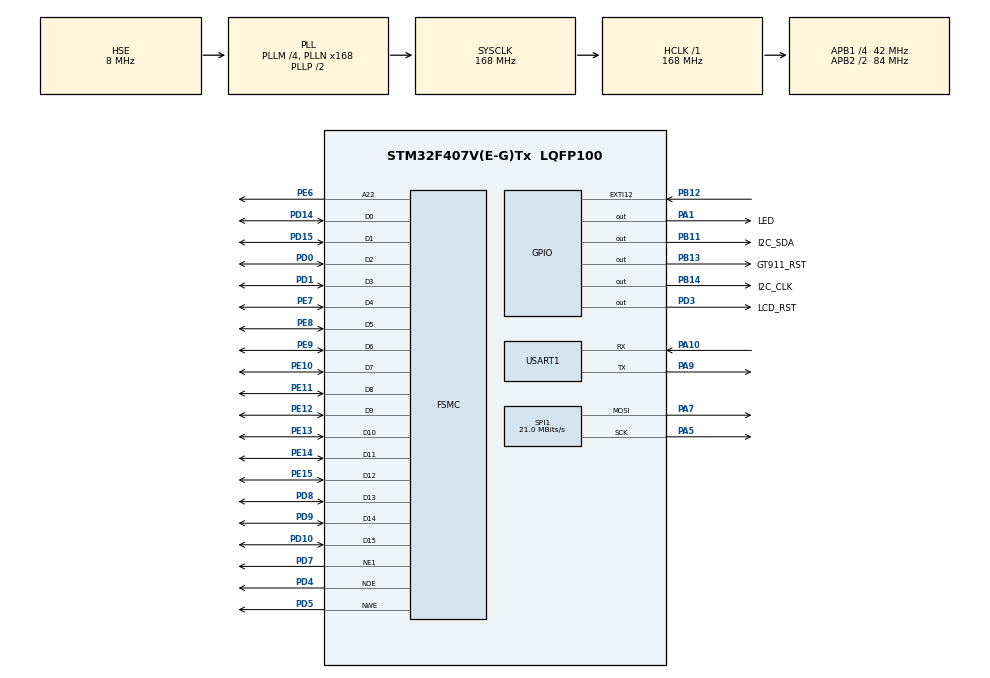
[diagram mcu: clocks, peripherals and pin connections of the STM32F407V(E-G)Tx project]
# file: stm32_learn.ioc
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Dma.MEMTOMEM.0.Direction=DMA_MEMORY_TO_MEMORY
Dma.MEMTOMEM.0.FIFOMode=DMA_FIFOMODE_ENABLE
Dma.MEMTOMEM.0.FIFOThreshold=DMA_FIFO_THRESHOLD_FULL
Dma.MEMTOMEM.0.Instance=DMA2_Stream0
Dma.MEMTOMEM.0.MemBurst=DMA_MBURST_SINGLE
Dma.MEMTOMEM.0.MemDataAlignment=DMA_MDATAALIGN_HALFWORD
Dma.MEMTOMEM.0.MemInc=DMA_MINC_DISABLE
Dma.MEMTOMEM.0.Mode=DMA_NORMAL
Dma.MEMTOMEM.0.PeriphBurst=DMA_PBURST_SINGLE
Dma.MEMTOMEM.0.PeriphDataAlignment=DMA_PDATAALIGN_HALFWORD
Dma.MEMTOMEM.0.PeriphInc=DMA_PINC_ENABLE
Dma.MEMTOMEM.0.Priority=DMA_PRIORITY_HIGH
Dma.Request0=MEMTOMEM
FSMC.AddressSetupTime1=1
FSMC.BusTurnAroundDuration1=0
FSMC.DataSetupTime1=1
FSMC.ExtendedMode1=FSMC_EXTENDED_MODE_DISABLE
Mcu.Family=STM32F4
Mcu.Name=STM32F407V(E-G)Tx
Mcu.Package=LQFP100
NVIC.PriorityGroup=NVIC_PRIORITYGROUP_4
PA1.GPIO_Label=LED
PA1.Signal=GPIO_Output
PA10.Mode=Asynchronous
PA10.Signal=USART1_RX
PA13.Mode=Serial_Wire
PA13.Signal=SYS_JTMS-SWDIO
PA14.Mode=Serial_Wire
PA14.Signal=SYS_JTCK-SWCLK
PA5.Mode=TX_Only_Simplex_Unidirect_Master
PA5.Signal=SPI1_SCK
PA7.Mode=TX_Only_Simplex_Unidirect_Master
PA7.Signal=SPI1_MOSI
PA9.Mode=Asynchronous
PA9.Signal=USART1_TX
PB11.GPIO_Label=I2C_SDA
PB11.GPIO_ModeDefaultOutputPP=GPIO_MODE_OUTPUT_PP
PB11.GPIO_PuPd=GPIO_PULLUP
PB11.GPIO_Speed=GPIO_SPEED_FREQ_HIGH
PB11.Signal=GPIO_Output
PB12.Signal=GPXTI12
PB13.GPIO_Label=GT911_RST
PB13.GPIO_PuPd=GPIO_PULLUP
PB13.PinState=GPIO_PIN_RESET
PB13.Signal=GPIO_Output
PB14.GPIO_Label=I2C_CLK
PB14.GPIO_ModeDefaultOutputPP=GPIO_MODE_OUTPUT_PP
PB14.GPIO_PuPd=GPIO_PULLUP
PB14.GPIO_Speed=GPIO_SPEED_FREQ_HIGH
PB14.Signal=GPIO_Output
PC14-OSC32_IN.Mode=LSE-External-Oscillator
PC14-OSC32_IN.Signal=RCC_OSC32_IN
PC15-OSC32_OUT.Mode=LSE-External-Oscillator
PC15-OSC32_OUT.Signal=RCC_OSC32_OUT
PD0.Mode=16b-d1
PD0.Signal=FSMC_D2
PD1.Mode=16b-d1
PD1.Signal=FSMC_D3
PD10.Mode=16b-d1
PD10.Signal=FSMC_D15
PD14.Mode=16b-d1
PD14.Signal=FSMC_D0
PD15.Mode=16b-d1
PD15.Signal=FSMC_D1
PD3.GPIO_Label=LCD_RST
PD3.Signal=GPIO_Output
PD4.Mode=Lcd1
PD4.Signal=FSMC_NOE
PD5.Mode=Lcd1
PD5.Signal=FSMC_NWE
PD7.Mode=NorPsramChipSelect1_1
PD7.Signal=FSMC_NE1
PD8.Mode=16b-d1
PD8.Signal=FSMC_D13
PD9.Mode=16b-d1
PD9.Signal=FSMC_D14
PE10.Mode=16b-d1
PE10.Signal=FSMC_D7
PE11.Mode=16b-d1
PE11.Signal=FSMC_D8
PE12.Mode=16b-d1
PE12.Signal=FSMC_D9
PE13.Mode=16b-d1
PE13.Signal=FSMC_D10
PE14.Mode=16b-d1
PE14.Signal=FSMC_D11
PE15.Mode=16b-d1
PE15.Signal=FSMC_D12
PE6.Mode=A22_1
PE6.Signal=FSMC_A22
PE7.Mode=16b-d1
PE7.Signal=FSMC_D4
PE8.Mode=16b-d1
PE8.Signal=FSMC_D5
PE9.Mode=16b-d1
PE9.Signal=FSMC_D6
PH0-OSC_IN.Mode=HSE-External-Oscillator
PH0-OSC_IN.Signal=RCC_OSC_IN
PH1-OSC_OUT.Mode=HSE-External-Oscillator
PH1-OSC_OUT.Signal=RCC_OSC_OUT
ProjectManager.HeapSize=0x200
ProjectManager.StackSize=0x400
ProjectManager.TargetToolchain=CMake
RCC.48MHZClocksFreq_Value=84000000
RCC.AHBFreq_Value=168000000
RCC.APB1CLKDivider=RCC_HCLK_DIV4
RCC.APB1Freq_Value=42000000
RCC.APB1TimFreq_Value=84000000
RCC.APB2CLKDivider=RCC_HCLK_DIV2
RCC.APB2Freq_Value=84000000
RCC.APB2TimFreq_Value=168000000
RCC.CortexFreq_Value=168000000
RCC.HCLKFreq_Value=168000000
RCC.HSE_VALUE=8000000
RCC.HSI_VALUE=16000000
RCC.PLLM=4
RCC.PLLMUL=RCC_PLL_MUL9
RCC.PLLN=168
RCC.PLLSourceVirtual=RCC_PLLSOURCE_HSE
RCC.SYSCLKFreq_VALUE=168000000
RCC.SYSCLKSource=RCC_SYSCLKSOURCE_PLLCLK
RCC.USBFreq_Value=72000000
RCC.VCOOutputFreq_Value=336000000
SPI1.BaudRatePrescaler=SPI_BAUDRATEPRESCALER_4
SPI1.CLKPhase=SPI_PHASE_1EDGE
SPI1.CLKPolarity=SPI_POLARITY_LOW
SPI1.CalculateBaudRate=21.0 MBits/s
SPI1.Direction=SPI_DIRECTION_2LINES
SPI1.Mode=SPI_MODE_MASTER
SPI1.VirtualType=VM_MASTER
USART1.VirtualMode=VM_ASYNC
board=custom

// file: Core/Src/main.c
/* USER CODE BEGIN Header */
/**
  ******************************************************************************
  * @file           : main.c
  * @brief          : Main program body
  ******************************************************************************
  * @attention
  *
  * Copyright (c) 2026 STMicroelectronics.
  * All rights reserved.
  *
  * This software is licensed under terms that can be found in the LICENSE file
  * in the root directory of this software component.
  * If no LICENSE file comes with this software, it is provided AS-IS.
  *
  ******************************************************************************
  */
/* USER CODE END Header */
#include "main.h"

SPI_HandleTypeDef hspi1;

UART_HandleTypeDef huart1;

DMA_HandleTypeDef hdma_memtomem_dma2_stream0;
SRAM_HandleTypeDef hsram1;

void SystemClock_Config(void);
static void MX_GPIO_Init(void);
static void MX_DMA_Init(void);
static void MX_FSMC_Init(void);
static void MX_SPI1_Init(void);
static void MX_USART1_UART_Init(void);

/* USER CODE BEGIN 0 */
int mymain(void);
/* USER CODE END 0 */

int main(void)
{

  /* MCU Configuration--------------------------------------------------------*/

  /* Reset of all peripherals, Initializes the Flash interface and the Systick. */
  HAL_Init();

  /* Configure the system clock */
  SystemClock_Config();

  /* Initialize all configured peripherals */
  MX_GPIO_Init();
  MX_DMA_Init();
  MX_FSMC_Init();
  MX_SPI1_Init();
  MX_USART1_UART_Init();
  /* USER CODE BEGIN 2 */
    if (mymain() != 0)
    {
      Error_Handler();
    }

  /* USER CODE END 2 */

  /* Infinite loop */
  while (1)
  {

  }
}

void SystemClock_Config(void)
{
  RCC_OscInitTypeDef RCC_OscInitStruct = {0};
  RCC_ClkInitTypeDef RCC_ClkInitStruct = {0};

  /** Configure the main internal regulator output voltage
  */
  __HAL_RCC_PWR_CLK_ENABLE();
  __HAL_PWR_VOLTAGESCALING_CONFIG(PWR_REGULATOR_VOLTAGE_SCALE1);

  /** Initializes the RCC Oscillators according to the specified parameters
  * in the RCC_OscInitTypeDef structure.
  */
  RCC_OscInitStruct.OscillatorType = RCC_OSCILLATORTYPE_HSE;
  RCC_OscInitStruct.HSEState = RCC_HSE_ON;
  RCC_OscInitStruct.PLL.PLLState = RCC_PLL_ON;
  RCC_OscInitStruct.PLL.PLLSource = RCC_PLLSOURCE_HSE;
  RCC_OscInitStruct.PLL.PLLM = 4;
  RCC_OscInitStruct.PLL.PLLN = 168;
  RCC_OscInitStruct.PLL.PLLP = RCC_PLLP_DIV2;
  RCC_OscInitStruct.PLL.PLLQ = 4;
  if (HAL_RCC_OscConfig(&RCC_OscInitStruct) != HAL_OK)
  {
    Error_Handler();
  }

  /** Initializes the CPU, AHB and APB buses clocks
  */
  RCC_ClkInitStruct.ClockType = RCC_CLOCKTYPE_HCLK|RCC_CLOCKTYPE_SYSCLK
                              |RCC_CLOCKTYPE_PCLK1|RCC_CLOCKTYPE_PCLK2;
  RCC_ClkInitStruct.SYSCLKSource = RCC_SYSCLKSOURCE_PLLCLK;
  RCC_ClkInitStruct.AHBCLKDivider = RCC_SYSCLK_DIV1;
  RCC_ClkInitStruct.APB1CLKDivider = RCC_HCLK_DIV4;
  RCC_ClkInitStruct.APB2CLKDivider = RCC_HCLK_DIV2;

  if (HAL_RCC_ClockConfig(&RCC_ClkInitStruct, FLASH_LATENCY_5) != HAL_OK)
  {
    Error_Handler();
  }
}

static void MX_SPI1_Init(void)
{

  /* SPI1 parameter configuration*/
  hspi1.Instance = SPI1;
  hspi1.Init.Mode = SPI_MODE_MASTER;
  hspi1.Init.Direction = SPI_DIRECTION_2LINES;
  hspi1.Init.DataSize = SPI_DATASIZE_8BIT;
  hspi1.Init.CLKPolarity = SPI_POLARITY_LOW;
  hspi1.Init.CLKPhase = SPI_PHASE_1EDGE;
  hspi1.Init.NSS = SPI_NSS_SOFT;
  hspi1.Init.BaudRatePrescaler = SPI_BAUDRATEPRESCALER_4;
  hspi1.Init.FirstBit = SPI_FIRSTBIT_MSB;
  hspi1.Init.TIMode = SPI_TIMODE_DISABLE;
  hspi1.Init.CRCCalculation = SPI_CRCCALCULATION_DISABLE;
  hspi1.Init.CRCPolynomial = 10;
  if (HAL_SPI_Init(&hspi1) != HAL_OK)
  {
    Error_Handler();
  }

}

static void MX_USART1_UART_Init(void)
{

  huart1.Instance = USART1;
  huart1.Init.BaudRate = 115200;
  huart1.Init.WordLength = UART_WORDLENGTH_8B;
  huart1.Init.StopBits = UART_STOPBITS_1;
  huart1.Init.Parity = UART_PARITY_NONE;
  huart1.Init.Mode = UART_MODE_TX_RX;
  huart1.Init.HwFlowCtl = UART_HWCONTROL_NONE;
  huart1.Init.OverSampling = UART_OVERSAMPLING_16;
  if (HAL_UART_Init(&huart1) != HAL_OK)
  {
    Error_Handler();
  }

}

static void MX_DMA_Init(void)
{

  /* DMA controller clock enable */
  __HAL_RCC_DMA2_CLK_ENABLE();

  /* Configure DMA request hdma_memtomem_dma2_stream0 on DMA2_Stream0 */
  hdma_memtomem_dma2_stream0.Instance = DMA2_Stream0;
  hdma_memtomem_dma2_stream0.Init.Channel = DMA_CHANNEL_0;
  hdma_memtomem_dma2_stream0.Init.Direction = DMA_MEMORY_TO_MEMORY;
  hdma_memtomem_dma2_stream0.Init.PeriphInc = DMA_PINC_ENABLE;
  hdma_memtomem_dma2_stream0.Init.MemInc = DMA_MINC_DISABLE;
  hdma_memtomem_dma2_stream0.Init.PeriphDataAlignment = DMA_PDATAALIGN_HALFWORD;
  hdma_memtomem_dma2_stream0.Init.MemDataAlignment = DMA_MDATAALIGN_HALFWORD;
  hdma_memtomem_dma2_stream0.Init.Mode = DMA_NORMAL;
  hdma_memtomem_dma2_stream0.Init.Priority = DMA_PRIORITY_HIGH;
  hdma_memtomem_dma2_stream0.Init.FIFOMode = DMA_FIFOMODE_ENABLE;
  hdma_memtomem_dma2_stream0.Init.FIFOThreshold = DMA_FIFO_THRESHOLD_FULL;
  hdma_memtomem_dma2_stream0.Init.MemBurst = DMA_MBURST_SINGLE;
  hdma_memtomem_dma2_stream0.Init.PeriphBurst = DMA_PBURST_SINGLE;
  if (HAL_DMA_Init(&hdma_memtomem_dma2_stream0) != HAL_OK)
  {
    Error_Handler( );
  }

}

static void MX_GPIO_Init(void)
{
  GPIO_InitTypeDef GPIO_InitStruct = {0};

  /* GPIO Ports Clock Enable */
  __HAL_RCC_GPIOE_CLK_ENABLE();
  __HAL_RCC_GPIOC_CLK_ENABLE();
  __HAL_RCC_GPIOH_CLK_ENABLE();
  __HAL_RCC_GPIOA_CLK_ENABLE();
  __HAL_RCC_GPIOB_CLK_ENABLE();
  __HAL_RCC_GPIOD_CLK_ENABLE();

  /*Configure GPIO pin Output Level */
  HAL_GPIO_WritePin(LED_GPIO_Port, LED_Pin, GPIO_PIN_RESET);

  /*Configure GPIO pin Output Level */
  HAL_GPIO_WritePin(GPIOB, I2C_SDA_Pin|GT911_RST_Pin|I2C_CLK_Pin, GPIO_PIN_RESET);

  /*Configure GPIO pin Output Level */
  HAL_GPIO_WritePin(LCD_RST_GPIO_Port, LCD_RST_Pin, GPIO_PIN_RESET);

  /*Configure GPIO pin : LED_Pin */
  GPIO_InitStruct.Pin = LED_Pin;
  GPIO_InitStruct.Mode = GPIO_MODE_OUTPUT_PP;
  GPIO_InitStruct.Pull = GPIO_NOPULL;
  GPIO_InitStruct.Speed = GPIO_SPEED_FREQ_LOW;
  HAL_GPIO_Init(LED_GPIO_Port, &GPIO_InitStruct);

  /*Configure GPIO pins : I2C_SDA_Pin I2C_CLK_Pin */
  GPIO_InitStruct.Pin = I2C_SDA_Pin|I2C_CLK_Pin;
  GPIO_InitStruct.Mode = GPIO_MODE_OUTPUT_PP;
  GPIO_InitStruct.Pull = GPIO_PULLUP;
  GPIO_InitStruct.Speed = GPIO_SPEED_FREQ_HIGH;
  HAL_GPIO_Init(GPIOB, &GPIO_InitStruct);

  /*Configure GPIO pin : PB12 */
  GPIO_InitStruct.Pin = GPIO_PIN_12;
  GPIO_InitStruct.Mode = GPIO_MODE_IT_RISING;
  GPIO_InitStruct.Pull = GPIO_NOPULL;
  HAL_GPIO_Init(GPIOB, &GPIO_InitStruct);

  /*Configure GPIO pin : GT911_RST_Pin */
  GPIO_InitStruct.Pin = GT911_RST_Pin;
  GPIO_InitStruct.Mode = GPIO_MODE_OUTPUT_PP;
  GPIO_InitStruct.Pull = GPIO_PULLUP;
  GPIO_InitStruct.Speed = GPIO_SPEED_FREQ_LOW;
  HAL_GPIO_Init(GT911_RST_GPIO_Port, &GPIO_InitStruct);

  /*Configure GPIO pin : LCD_RST_Pin */
  GPIO_InitStruct.Pin = LCD_RST_Pin;
  GPIO_InitStruct.Mode = GPIO_MODE_OUTPUT_PP;
  GPIO_InitStruct.Pull = GPIO_NOPULL;
  GPIO_InitStruct.Speed = GPIO_SPEED_FREQ_LOW;
  HAL_GPIO_Init(LCD_RST_GPIO_Port, &GPIO_InitStruct);

}

/* FSMC initialization function */
static void MX_FSMC_Init(void)
{

  FSMC_NORSRAM_TimingTypeDef Timing = {0};

  /** Perform the SRAM1 memory initialization sequence
  */
  hsram1.Instance = FSMC_NORSRAM_DEVICE;
  hsram1.Extended = FSMC_NORSRAM_EXTENDED_DEVICE;
  /* hsram1.Init */
  hsram1.Init.NSBank = FSMC_NORSRAM_BANK1;
  hsram1.Init.DataAddressMux = FSMC_DATA_ADDRESS_MUX_DISABLE;
  hsram1.Init.MemoryType = FSMC_MEMORY_TYPE_SRAM;
  hsram1.Init.MemoryDataWidth = FSMC_NORSRAM_MEM_BUS_WIDTH_16;
  hsram1.Init.BurstAccessMode = FSMC_BURST_ACCESS_MODE_DISABLE;
  hsram1.Init.WaitSignalPolarity = FSMC_WAIT_SIGNAL_POLARITY_LOW;
  hsram1.Init.WrapMode = FSMC_WRAP_MODE_DISABLE;
  hsram1.Init.WaitSignalActive = FSMC_WAIT_TIMING_BEFORE_WS;
  hsram1.Init.WriteOperation = FSMC_WRITE_OPERATION_ENABLE;
  hsram1.Init.WaitSignal = FSMC_WAIT_SIGNAL_DISABLE;
  hsram1.Init.ExtendedMode = FSMC_EXTENDED_MODE_DISABLE;
  hsram1.Init.AsynchronousWait = FSMC_ASYNCHRONOUS_WAIT_DISABLE;
  hsram1.Init.WriteBurst = FSMC_WRITE_BURST_DISABLE;
  hsram1.Init.PageSize = FSMC_PAGE_SIZE_NONE;
  /* Timing */
  Timing.AddressSetupTime = 1;
  Timing.AddressHoldTime = 15;
  Timing.DataSetupTime = 1;
  Timing.BusTurnAroundDuration = 0;
  Timing.CLKDivision = 16;
  Timing.DataLatency = 17;
  Timing.AccessMode = FSMC_ACCESS_MODE_A;
  /* ExtTiming */

  if (HAL_SRAM_Init(&hsram1, &Timing, NULL) != HAL_OK)
  {
    Error_Handler( );
  }

}

void Error_Handler(void)
{
  __disable_irq();
  while (1)
  {
  }
}
